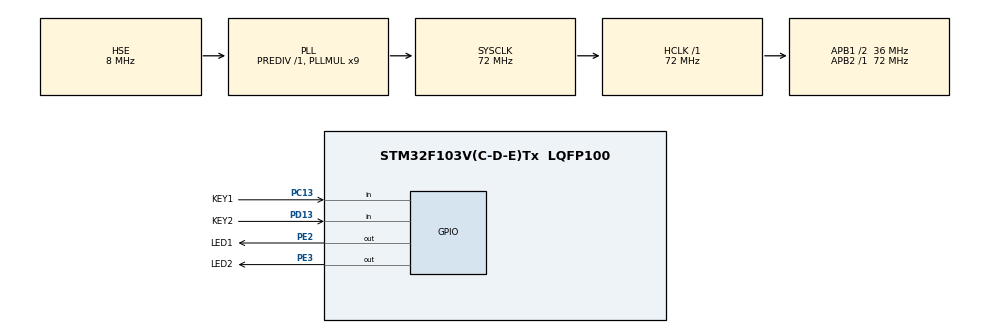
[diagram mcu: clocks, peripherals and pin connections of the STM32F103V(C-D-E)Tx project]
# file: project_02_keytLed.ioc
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Mcu.Family=STM32F1
Mcu.Name=STM32F103V(C-D-E)Tx
Mcu.Package=LQFP100
NVIC.PriorityGroup=NVIC_PRIORITYGROUP_4
OSC_IN.Mode=HSE-External-Oscillator
OSC_IN.Signal=RCC_OSC_IN
OSC_OUT.Mode=HSE-External-Oscillator
OSC_OUT.Signal=RCC_OSC_OUT
PA13.Mode=Serial_Wire
PA13.Signal=SYS_JTMS-SWDIO
PA14.Mode=Serial_Wire
PA14.Signal=SYS_JTCK-SWCLK
PC13-TAMPER-RTC.GPIO_Label=KEY1
PC13-TAMPER-RTC.GPIO_Mode=GPIO_MODE_INPUT
PC13-TAMPER-RTC.GPIO_PuPd=GPIO_PULLUP
PC13-TAMPER-RTC.Signal=GPIO_Input
PC14-OSC32_IN.Mode=LSE-External-Oscillator
PC14-OSC32_IN.Signal=RCC_OSC32_IN
PC15-OSC32_OUT.Mode=LSE-External-Oscillator
PC15-OSC32_OUT.Signal=RCC_OSC32_OUT
PD13.GPIO_Label=KEY2
PD13.GPIO_PuPd=GPIO_PULLUP
PD13.Signal=GPIO_Input
PE2.GPIO_Label=LED1
PE2.PinState=GPIO_PIN_SET
PE2.Signal=GPIO_Output
PE3.GPIO_Label=LED2
PE3.GPIO_ModeDefaultOutputPP=GPIO_MODE_OUTPUT_PP
PE3.PinState=GPIO_PIN_SET
PE3.Signal=GPIO_Output
ProjectManager.HeapSize=0x200
ProjectManager.StackSize=0x400
ProjectManager.TargetToolchain=MDK-ARM V5
RCC.AHBFreq_Value=72000000
RCC.APB1CLKDivider=RCC_HCLK_DIV2
RCC.APB1Freq_Value=36000000
RCC.APB1TimFreq_Value=72000000
RCC.APB2Freq_Value=72000000
RCC.APB2TimFreq_Value=72000000
RCC.HCLKFreq_Value=72000000
RCC.PLLMUL=RCC_PLL_MUL9
RCC.PLLSourceVirtual=RCC_PLLSOURCE_HSE
RCC.SYSCLKFreq_VALUE=72000000
RCC.SYSCLKSource=RCC_SYSCLKSOURCE_PLLCLK
RCC.TimSys_Div=SYSTICK_CLKSOURCE_HCLK_DIV8
RCC.USBFreq_Value=72000000
board=custom

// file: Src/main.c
/* USER CODE BEGIN Header */
/**
  ******************************************************************************
  * @file           : main.c
  * @brief          : Main program body
  ******************************************************************************
  * @attention
  *
  * <h2><center>&copy; Copyright (c) 2020 STMicroelectronics.
  * All rights reserved.</center></h2>
  *
  * This software component is licensed by ST under BSD 3-Clause license,
  * the "License"; You may not use this file except in compliance with the
  * License. You may obtain a copy of the License at:
  *                        opensource.org/licenses/BSD-3-Clause
  *
  ******************************************************************************
  */
/* USER CODE END Header */

#include "main.h"

void SystemClock_Config(void);

static void MX_GPIO_Init(void);

/* USER CODE BEGIN 0 */
//宏定义扫描按键 为了简化代码
#define KEY1 HAL_GPIO_ReadPin(GPIOC,GPIO_PIN_13)
#define KEY2 HAL_GPIO_ReadPin(GPIOD,GPIO_PIN_13)

void sca_key() {
    if (HAL_GPIO_ReadPin(GPIOC, GPIO_PIN_13) == GPIO_PIN_RESET) {
        HAL_Delay(100);
        if (HAL_GPIO_ReadPin(GPIOC, GPIO_PIN_13) == GPIO_PIN_SET) {
            //用或 同时给两个引脚赋值
            HAL_GPIO_TogglePin(GPIOE, GPIO_PIN_2 | GPIO_PIN_3);
            // HAL_GPIO_TogglePin(GPIOE, GPIO_PIN_3);
            while (HAL_GPIO_ReadPin(GPIOC, GPIO_PIN_13) == GPIO_PIN_RESET);
        }
    }
    //使用宏定义简化代码 GPIO_PIN_RESET = 0
    if (KEY2 == 0) {
        HAL_Delay(100);
        if (KEY2 == 0) {
            HAL_GPIO_TogglePin(GPIOE, GPIO_PIN_2);
            HAL_Delay(500);
            HAL_GPIO_TogglePin(GPIOE, GPIO_PIN_3 | GPIO_PIN_1);
            while (HAL_GPIO_ReadPin(GPIOC, GPIO_PIN_13) == GPIO_PIN_RESET);
        }
    }
}
/* USER CODE END 0 */

int main(void) {

    /* MCU Configuration--------------------------------------------------------*/

    /* Reset of all peripherals, Initializes the Flash interface and the Systick. */
    HAL_Init();

    /* Configure the system clock */
    SystemClock_Config();

    /* Initialize all configured peripherals */
    MX_GPIO_Init();

    /* Infinite loop */
    /* USER CODE BEGIN WHILE */
    while (1) {
        sca_key();
        /* USER CODE END WHILE */

    }
}

void SystemClock_Config(void) {
    RCC_OscInitTypeDef RCC_OscInitStruct = {0};
    RCC_ClkInitTypeDef RCC_ClkInitStruct = {0};

    /** Initializes the CPU, AHB and APB busses clocks
    */
    RCC_OscInitStruct.OscillatorType = RCC_OSCILLATORTYPE_HSE;
    RCC_OscInitStruct.HSEState = RCC_HSE_ON;
    RCC_OscInitStruct.HSEPredivValue = RCC_HSE_PREDIV_DIV1;
    RCC_OscInitStruct.HSIState = RCC_HSI_ON;
    RCC_OscInitStruct.PLL.PLLState = RCC_PLL_ON;
    RCC_OscInitStruct.PLL.PLLSource = RCC_PLLSOURCE_HSE;
    RCC_OscInitStruct.PLL.PLLMUL = RCC_PLL_MUL9;
    if (HAL_RCC_OscConfig(&RCC_OscInitStruct) != HAL_OK) {
        Error_Handler();
    }
    /** Initializes the CPU, AHB and APB busses clocks
    */
    RCC_ClkInitStruct.ClockType = RCC_CLOCKTYPE_HCLK | RCC_CLOCKTYPE_SYSCLK
                                  | RCC_CLOCKTYPE_PCLK1 | RCC_CLOCKTYPE_PCLK2;
    RCC_ClkInitStruct.SYSCLKSource = RCC_SYSCLKSOURCE_PLLCLK;
    RCC_ClkInitStruct.AHBCLKDivider = RCC_SYSCLK_DIV1;
    RCC_ClkInitStruct.APB1CLKDivider = RCC_HCLK_DIV2;
    RCC_ClkInitStruct.APB2CLKDivider = RCC_HCLK_DIV1;

    if (HAL_RCC_ClockConfig(&RCC_ClkInitStruct, FLASH_LATENCY_2) != HAL_OK) {
        Error_Handler();
    }
}

static void MX_GPIO_Init(void) {
    GPIO_InitTypeDef GPIO_InitStruct = {0};

    /* GPIO Ports Clock Enable */
    __HAL_RCC_GPIOE_CLK_ENABLE();
    __HAL_RCC_GPIOC_CLK_ENABLE();
    __HAL_RCC_GPIOD_CLK_ENABLE();
    __HAL_RCC_GPIOA_CLK_ENABLE();

    /*Configure GPIO pin Output Level */
    HAL_GPIO_WritePin(GPIOE, LED1_Pin | LED2_Pin | LED3_Pin, GPIO_PIN_SET);

    /*Configure GPIO pins : LED1_Pin LED2_Pin LED3_Pin*/
    GPIO_InitStruct.Pin = LED1_Pin | LED2_Pin | LED3_Pin;
    GPIO_InitStruct.Mode = GPIO_MODE_OUTPUT_PP;
    GPIO_InitStruct.Pull = GPIO_NOPULL;
    GPIO_InitStruct.Speed = GPIO_SPEED_FREQ_LOW;
    HAL_GPIO_Init(GPIOE, &GPIO_InitStruct);

    /*Configure GPIO pin : KEY1_Pin */
    GPIO_InitStruct.Pin = KEY1_Pin;
    GPIO_InitStruct.Mode = GPIO_MODE_INPUT;
    GPIO_InitStruct.Pull = GPIO_PULLUP;
    HAL_GPIO_Init(KEY1_GPIO_Port, &GPIO_InitStruct);

    /*Configure GPIO pin : KEY2_Pin */
    GPIO_InitStruct.Pin = KEY2_Pin;
    GPIO_InitStruct.Mode = GPIO_MODE_INPUT;
    GPIO_InitStruct.Pull = GPIO_PULLUP;
    HAL_GPIO_Init(KEY2_GPIO_Port, &GPIO_InitStruct);

}

void Error_Handler(void) {
}

/************************ (C) COPYRIGHT STMicroelectronics *****END OF FILE****/
